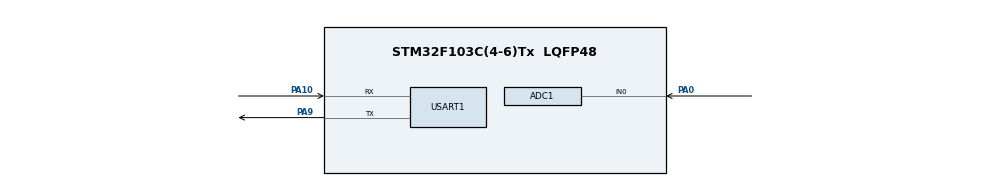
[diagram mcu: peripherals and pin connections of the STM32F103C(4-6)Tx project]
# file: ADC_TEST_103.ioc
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ADC1.Channel-0\#ChannelRegularConversion=ADC_CHANNEL_0
ADC1.NbrOfConversionFlag=1
ADC1.Rank-0\#ChannelRegularConversion=1
ADC1.SamplingTime-0\#ChannelRegularConversion=ADC_SAMPLETIME_1CYCLE_5
ADC1.master=1
Mcu.Family=STM32F1
Mcu.Name=STM32F103C(4-6)Tx
Mcu.Package=LQFP48
NVIC.PriorityGroup=NVIC_PRIORITYGROUP_4
PA0-WKUP.Signal=ADCx_IN0
PA10.Mode=Asynchronous
PA10.Signal=USART1_RX
PA9.Mode=Asynchronous
PA9.Signal=USART1_TX
PD0-OSC_IN.Mode=HSE-External-Oscillator
PD0-OSC_IN.Signal=RCC_OSC_IN
PD1-OSC_OUT.Mode=HSE-External-Oscillator
PD1-OSC_OUT.Signal=RCC_OSC_OUT
ProjectManager.HeapSize=0x200
ProjectManager.StackSize=0x400
ProjectManager.TargetToolchain=STM32CubeIDE
RCC.APB1Freq_Value=8000000
RCC.APB2Freq_Value=8000000
SH.ADCx_IN0.0=ADC1_IN0,IN0
USART1.VirtualMode=VM_ASYNC
board=custom

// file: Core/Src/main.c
/* USER CODE BEGIN Header */
/**
  ******************************************************************************
  * @file           : main.c
  * @brief          : Main program body
  ******************************************************************************
  * @attention
  *
  * Copyright (c) 2023 STMicroelectronics.
  * All rights reserved.
  *
  * This software is licensed under terms that can be found in the LICENSE file
  * in the root directory of this software component.
  * If no LICENSE file comes with this software, it is provided AS-IS.
  *
  ******************************************************************************
  */
/* USER CODE END Header */
#include "main.h"
#include "stdio.h"

ADC_HandleTypeDef hadc1;

UART_HandleTypeDef huart1;

// Define the GPIO ports for the seven-segment display

void SystemClock_Config(void);
static void MX_GPIO_Init(void);
static void MX_ADC1_Init(void);
static void MX_USART1_UART_Init(void);

int main(void)
{
	float test;
	char msg[10];

  /* MCU Configuration--------------------------------------------------------*/

  /* Reset of all peripherals, Initializes the Flash interface and the Systick. */
  HAL_Init();

  /* USER CODE BEGIN Init */

  unsigned char arr[10] = {0x3F,0x06,0x5B,0x4F,0x66,0x6D,0x7D,0x07,0x7F,0x6F};
  int j;
  /* USER CODE END Init */

  /* Configure the system clock */
  SystemClock_Config();

  /* Initialize all configured peripherals */
  MX_GPIO_Init();
  MX_ADC1_Init();
  MX_USART1_UART_Init();

  /* Infinite loop */
  /* USER CODE BEGIN WHILE */

  while (1)
  {
	  HAL_ADC_Start(&hadc1);

	  HAL_ADC_PollForConversion(&hadc1,10000);

	  test =HAL_ADC_GetValue(&hadc1);

	//  test = test*0.001220703125;

	  //test= test*5/4096;

	  //sprintf(msg,"%.3f",test);

	  //HAL_UART_Transmit(&huart1,msg,strlen(msg),10000);

	  for(j=0; j<10; j++)
	  {
		  GPIOA -> ODR =arr[j];
		  HAL_Delay(1000);
	  }

	       // Clear the GPIO output data register

    /* USER CODE END WHILE */

  }
}

void SystemClock_Config(void)
{
  RCC_OscInitTypeDef RCC_OscInitStruct = {0};
  RCC_ClkInitTypeDef RCC_ClkInitStruct = {0};
  RCC_PeriphCLKInitTypeDef PeriphClkInit = {0};

  /** Initializes the RCC Oscillators according to the specified parameters
  * in the RCC_OscInitTypeDef structure.
  */
  RCC_OscInitStruct.OscillatorType = RCC_OSCILLATORTYPE_HSI;
  RCC_OscInitStruct.HSIState = RCC_HSI_ON;
  RCC_OscInitStruct.HSICalibrationValue = RCC_HSICALIBRATION_DEFAULT;
  RCC_OscInitStruct.PLL.PLLState = RCC_PLL_NONE;
  if (HAL_RCC_OscConfig(&RCC_OscInitStruct) != HAL_OK)
  {
    Error_Handler();
  }

  /** Initializes the CPU, AHB and APB buses clocks
  */
  RCC_ClkInitStruct.ClockType = RCC_CLOCKTYPE_HCLK|RCC_CLOCKTYPE_SYSCLK
                              |RCC_CLOCKTYPE_PCLK1|RCC_CLOCKTYPE_PCLK2;
  RCC_ClkInitStruct.SYSCLKSource = RCC_SYSCLKSOURCE_HSI;
  RCC_ClkInitStruct.AHBCLKDivider = RCC_SYSCLK_DIV1;
  RCC_ClkInitStruct.APB1CLKDivider = RCC_HCLK_DIV1;
  RCC_ClkInitStruct.APB2CLKDivider = RCC_HCLK_DIV1;

  if (HAL_RCC_ClockConfig(&RCC_ClkInitStruct, FLASH_LATENCY_0) != HAL_OK)
  {
    Error_Handler();
  }
  PeriphClkInit.PeriphClockSelection = RCC_PERIPHCLK_ADC;
  PeriphClkInit.AdcClockSelection = RCC_ADCPCLK2_DIV2;
  if (HAL_RCCEx_PeriphCLKConfig(&PeriphClkInit) != HAL_OK)
  {
    Error_Handler();
  }
}

static void MX_ADC1_Init(void)
{

  ADC_ChannelConfTypeDef sConfig = {0};

  /** Common config
  */
  hadc1.Instance = ADC1;
  hadc1.Init.ScanConvMode = ADC_SCAN_DISABLE;
  hadc1.Init.ContinuousConvMode = DISABLE;
  hadc1.Init.DiscontinuousConvMode = DISABLE;
  hadc1.Init.ExternalTrigConv = ADC_SOFTWARE_START;
  hadc1.Init.DataAlign = ADC_DATAALIGN_RIGHT;
  hadc1.Init.NbrOfConversion = 1;
  if (HAL_ADC_Init(&hadc1) != HAL_OK)
  {
    Error_Handler();
  }

  /** Configure Regular Channel
  */
  sConfig.Channel = ADC_CHANNEL_0;
  sConfig.Rank = ADC_REGULAR_RANK_1;
  sConfig.SamplingTime = ADC_SAMPLETIME_1CYCLE_5;
  if (HAL_ADC_ConfigChannel(&hadc1, &sConfig) != HAL_OK)
  {
    Error_Handler();
  }

}

static void MX_USART1_UART_Init(void)
{

  huart1.Instance = USART1;
  huart1.Init.BaudRate = 9600;
  huart1.Init.WordLength = UART_WORDLENGTH_8B;
  huart1.Init.StopBits = UART_STOPBITS_1;
  huart1.Init.Parity = UART_PARITY_NONE;
  huart1.Init.Mode = UART_MODE_TX_RX;
  huart1.Init.HwFlowCtl = UART_HWCONTROL_NONE;
  huart1.Init.OverSampling = UART_OVERSAMPLING_16;
  if (HAL_UART_Init(&huart1) != HAL_OK)
  {
    Error_Handler();
  }

}

static void MX_GPIO_Init(void)
{

  /* GPIO Ports Clock Enable */
  __HAL_RCC_GPIOD_CLK_ENABLE();
  __HAL_RCC_GPIOA_CLK_ENABLE();

}

void Error_Handler(void)
{
  __disable_irq();
  while (1)
  {
  }
}
